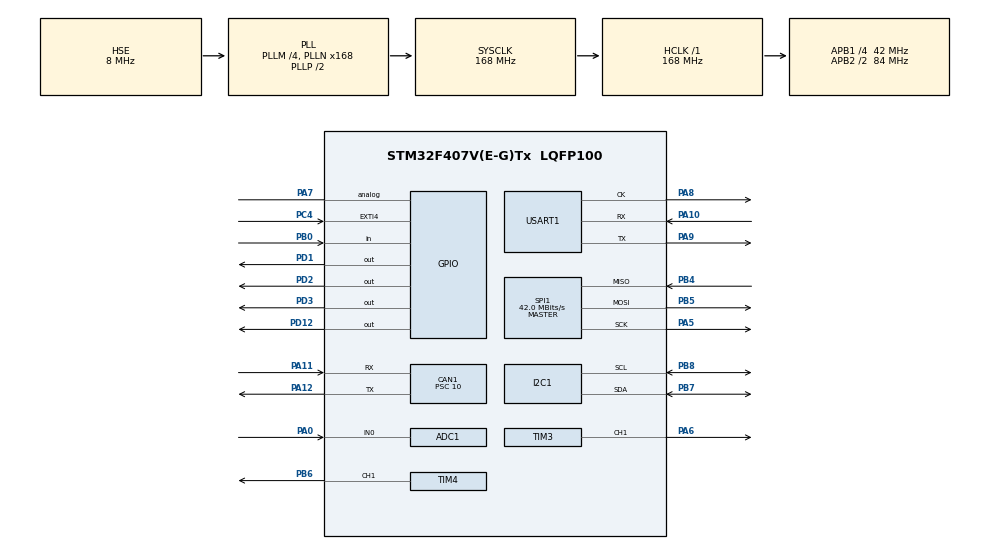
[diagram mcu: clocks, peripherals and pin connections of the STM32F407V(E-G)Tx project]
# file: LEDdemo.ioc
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ADC1.Channel-0\#ChannelRegularConversion=ADC_CHANNEL_0
ADC1.NbrOfConversionFlag=1
ADC1.Rank-0\#ChannelRegularConversion=1
ADC1.SamplingTime-0\#ChannelRegularConversion=ADC_SAMPLETIME_3CYCLES
ADC1.master=1
CAN1.BS1=CAN_BS1_5TQ
CAN1.BS2=CAN_BS2_5TQ
CAN1.CalculateTimeQuantum=238.0952380952381
CAN1.Prescaler=10
CAN1.SJW=CAN_SJW_4TQ
I2C1.I2C_Mode=I2C_Fast
Mcu.Family=STM32F4
Mcu.Name=STM32F407V(E-G)Tx
Mcu.Package=LQFP100
NVIC.PriorityGroup=NVIC_PRIORITYGROUP_4
NVIC.TIM2_IRQn=true\:1\:0\:true\:false\:true\:true\:true\:true
NVIC.TIM3_IRQn=true\:2\:0\:true\:false\:true\:true\:true\:true
PA0-WKUP.Signal=ADCx_IN0
PA10.Mode=Synchronous
PA10.Signal=USART1_RX
PA11.Mode=Master
PA11.Signal=CAN1_RX
PA12.Mode=Master
PA12.Signal=CAN1_TX
PA13.Mode=Serial_Wire
PA13.Signal=SYS_JTMS-SWDIO
PA14.Mode=Serial_Wire
PA14.Signal=SYS_JTCK-SWCLK
PA5.Mode=Full_Duplex_Master
PA5.Signal=SPI1_SCK
PA6.Signal=S_TIM3_CH1
PA7.PinState=GPIO_PIN_SET
PA7.Signal=SharedStack_PA7
PA7.Stacked=true
PA8.Mode=Synchronous
PA8.Signal=USART1_CK
PA9.Mode=Synchronous
PA9.Signal=USART1_TX
PB0.Signal=GPIO_Input
PB4.Mode=Full_Duplex_Master
PB4.Signal=SPI1_MISO
PB5.Mode=Full_Duplex_Master
PB5.Signal=SPI1_MOSI
PB6.Signal=S_TIM4_CH1
PB7.Mode=I2C
PB7.Signal=I2C1_SDA
PB8.Mode=I2C
PB8.Signal=I2C1_SCL
PC4.GPIO_ModeDefaultEXTI=GPIO_MODE_IT_RISING
PC4.GPIO_PuPd=GPIO_PULLUP
PC4.Signal=GPXTI4
PD1.PinState=GPIO_PIN_SET
PD1.Signal=GPIO_Output
PD12.Signal=GPIO_Output
PD2.PinState=GPIO_PIN_SET
PD2.Signal=GPIO_Output
PD3.PinState=GPIO_PIN_SET
PD3.Signal=GPIO_Output
PH0-OSC_IN.Mode=HSE-External-Oscillator
PH0-OSC_IN.Signal=RCC_OSC_IN
PH1-OSC_OUT.Mode=HSE-External-Oscillator
PH1-OSC_OUT.Signal=RCC_OSC_OUT
ProjectManager.HeapSize=0x200
ProjectManager.StackSize=0x400
ProjectManager.TargetToolchain=MDK-ARM V5.27
RCC.48MHZClocksFreq_Value=84000000
RCC.AHBFreq_Value=168000000
RCC.APB1CLKDivider=RCC_HCLK_DIV4
RCC.APB1Freq_Value=42000000
RCC.APB1TimFreq_Value=84000000
RCC.APB2CLKDivider=RCC_HCLK_DIV2
RCC.APB2Freq_Value=84000000
RCC.APB2TimFreq_Value=168000000
RCC.CortexFreq_Value=168000000
RCC.HCLKFreq_Value=168000000
RCC.HSE_VALUE=8000000
RCC.HSI_VALUE=16000000
RCC.LSE_VALUE=32768
RCC.PLLM=4
RCC.PLLN=168
RCC.PLLSourceVirtual=RCC_PLLSOURCE_HSE
RCC.SYSCLKFreq_VALUE=168000000
RCC.SYSCLKSource=RCC_SYSCLKSOURCE_PLLCLK
RCC.VCOOutputFreq_Value=336000000
SH.ADCx_IN0.0=ADC1_IN0,IN0
SH.S_TIM3_CH1.0=TIM3_CH1,PWM Generation1 CH1
SH.S_TIM4_CH1.0=TIM4_CH1,PWM Generation1 CH1
SH.SharedStack_PA7.0=GPIO_Analog+0
SH.SharedStack_PA7.1=GPIO_Output
SPI1.CalculateBaudRate=42.0 MBits/s
SPI1.Direction=SPI_DIRECTION_2LINES
SPI1.Mode=SPI_MODE_MASTER
SPI1.VirtualType=VM_MASTER
TIM2.Period=500000-1
TIM2.Prescaler=83
TIM3.Channel-PWM\ Generation1\ CH1=TIM_CHANNEL_1
TIM3.Period=1000-1
TIM3.Prescaler=83
TIM4.Channel-PWM\ Generation1\ CH1=TIM_CHANNEL_1
USART1.VirtualMode=VM_SYNC
VP_TIM14_VS_ClockSourceINT.Mode=Enable_Timer
VP_TIM2_VS_ClockSourceINT.Mode=Internal
VP_TIM3_VS_ClockSourceINT.Mode=Internal
VP_TIM4_VS_ClockSourceINT.Mode=Internal
board=custom

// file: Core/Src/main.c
/* USER CODE BEGIN Header */
/**
  ******************************************************************************
  * @file           : main.c
  * @brief          : Main program body
  ******************************************************************************
  * @attention
  *
  * <h2><center>&copy; Copyright (c) 2023 STMicroelectronics.
  * All rights reserved.</center></h2>
  *
  * This software component is licensed by ST under BSD 3-Clause license,
  * the "License"; You may not use this file except in compliance with the
  * License. You may obtain a copy of the License at:
  *                        opensource.org/licenses/BSD-3-Clause
  *
  ******************************************************************************
  */
/* USER CODE END Header */
#include "main.h"
#include "adc.h"
#include "can.h"
#include "i2c.h"
#include "spi.h"
#include "tim.h"
#include "usart.h"
#include "gpio.h"

void SystemClock_Config(void);
/* USER CODE BEGIN PFP */
int x;
/* USER CODE END PFP */

/* USER CODE BEGIN 0 */
void HAL_TIM_PeriodElapsedCallback(TIM_HandleTypeDef *htim)
{
	HAL_GPIO_TogglePin(GPIOA,GPIO_PIN_6);
	x++;
}

/* USER CODE END 0 */

int main(void)
{

  /* MCU Configuration--------------------------------------------------------*/

  /* Reset of all peripherals, Initializes the Flash interface and the Systick. */
  HAL_Init();

  /* Configure the system clock */
  SystemClock_Config();

  /* Initialize all configured peripherals */
  MX_GPIO_Init();
  MX_TIM2_Init();
  MX_I2C1_Init();
  MX_SPI1_Init();
  MX_USART1_Init();
  MX_ADC1_Init();
  MX_CAN1_Init();
  MX_TIM14_Init();
  MX_TIM3_Init();
  MX_TIM4_Init();
  /* USER CODE BEGIN 2 */
	//HAL_TIM_Base_Start_IT(&htim2);
	HAL_TIM_PWM_Start (&htim3,TIM_CHANNEL_1 );
  /* USER CODE END 2 */

  /* Infinite loop */
  while (1)
  {

    /* USER CODE BEGIN 3 */
		/*for(uint16_t i=1;i<1000;i++){
			__HAL_TIM_SetCompare (&htim3,TIM_CHANNEL_1,i);
			HAL_Delay (1);
		}
		for(uint16_t i=1000;i>0;i--){
			__HAL_TIM_SetCompare (&htim3,TIM_CHANNEL_1,i);
			HAL_Delay (1);
		}*/
  }
  /* USER CODE END 3 */
}

void SystemClock_Config(void)
{
  RCC_OscInitTypeDef RCC_OscInitStruct = {0};
  RCC_ClkInitTypeDef RCC_ClkInitStruct = {0};

  /** Configure the main internal regulator output voltage
  */
  __HAL_RCC_PWR_CLK_ENABLE();
  __HAL_PWR_VOLTAGESCALING_CONFIG(PWR_REGULATOR_VOLTAGE_SCALE1);
  /** Initializes the RCC Oscillators according to the specified parameters
  * in the RCC_OscInitTypeDef structure.
  */
  RCC_OscInitStruct.OscillatorType = RCC_OSCILLATORTYPE_HSE;
  RCC_OscInitStruct.HSEState = RCC_HSE_ON;
  RCC_OscInitStruct.PLL.PLLState = RCC_PLL_ON;
  RCC_OscInitStruct.PLL.PLLSource = RCC_PLLSOURCE_HSE;
  RCC_OscInitStruct.PLL.PLLM = 4;
  RCC_OscInitStruct.PLL.PLLN = 168;
  RCC_OscInitStruct.PLL.PLLP = RCC_PLLP_DIV2;
  RCC_OscInitStruct.PLL.PLLQ = 4;
  if (HAL_RCC_OscConfig(&RCC_OscInitStruct) != HAL_OK)
  {
    Error_Handler();
  }
  /** Initializes the CPU, AHB and APB buses clocks
  */
  RCC_ClkInitStruct.ClockType = RCC_CLOCKTYPE_HCLK|RCC_CLOCKTYPE_SYSCLK
                              |RCC_CLOCKTYPE_PCLK1|RCC_CLOCKTYPE_PCLK2;
  RCC_ClkInitStruct.SYSCLKSource = RCC_SYSCLKSOURCE_PLLCLK;
  RCC_ClkInitStruct.AHBCLKDivider = RCC_SYSCLK_DIV1;
  RCC_ClkInitStruct.APB1CLKDivider = RCC_HCLK_DIV4;
  RCC_ClkInitStruct.APB2CLKDivider = RCC_HCLK_DIV2;

  if (HAL_RCC_ClockConfig(&RCC_ClkInitStruct, FLASH_LATENCY_5) != HAL_OK)
  {
    Error_Handler();
  }
}

void Error_Handler(void)
{
}

/************************ (C) COPYRIGHT STMicroelectronics *****END OF FILE****/
